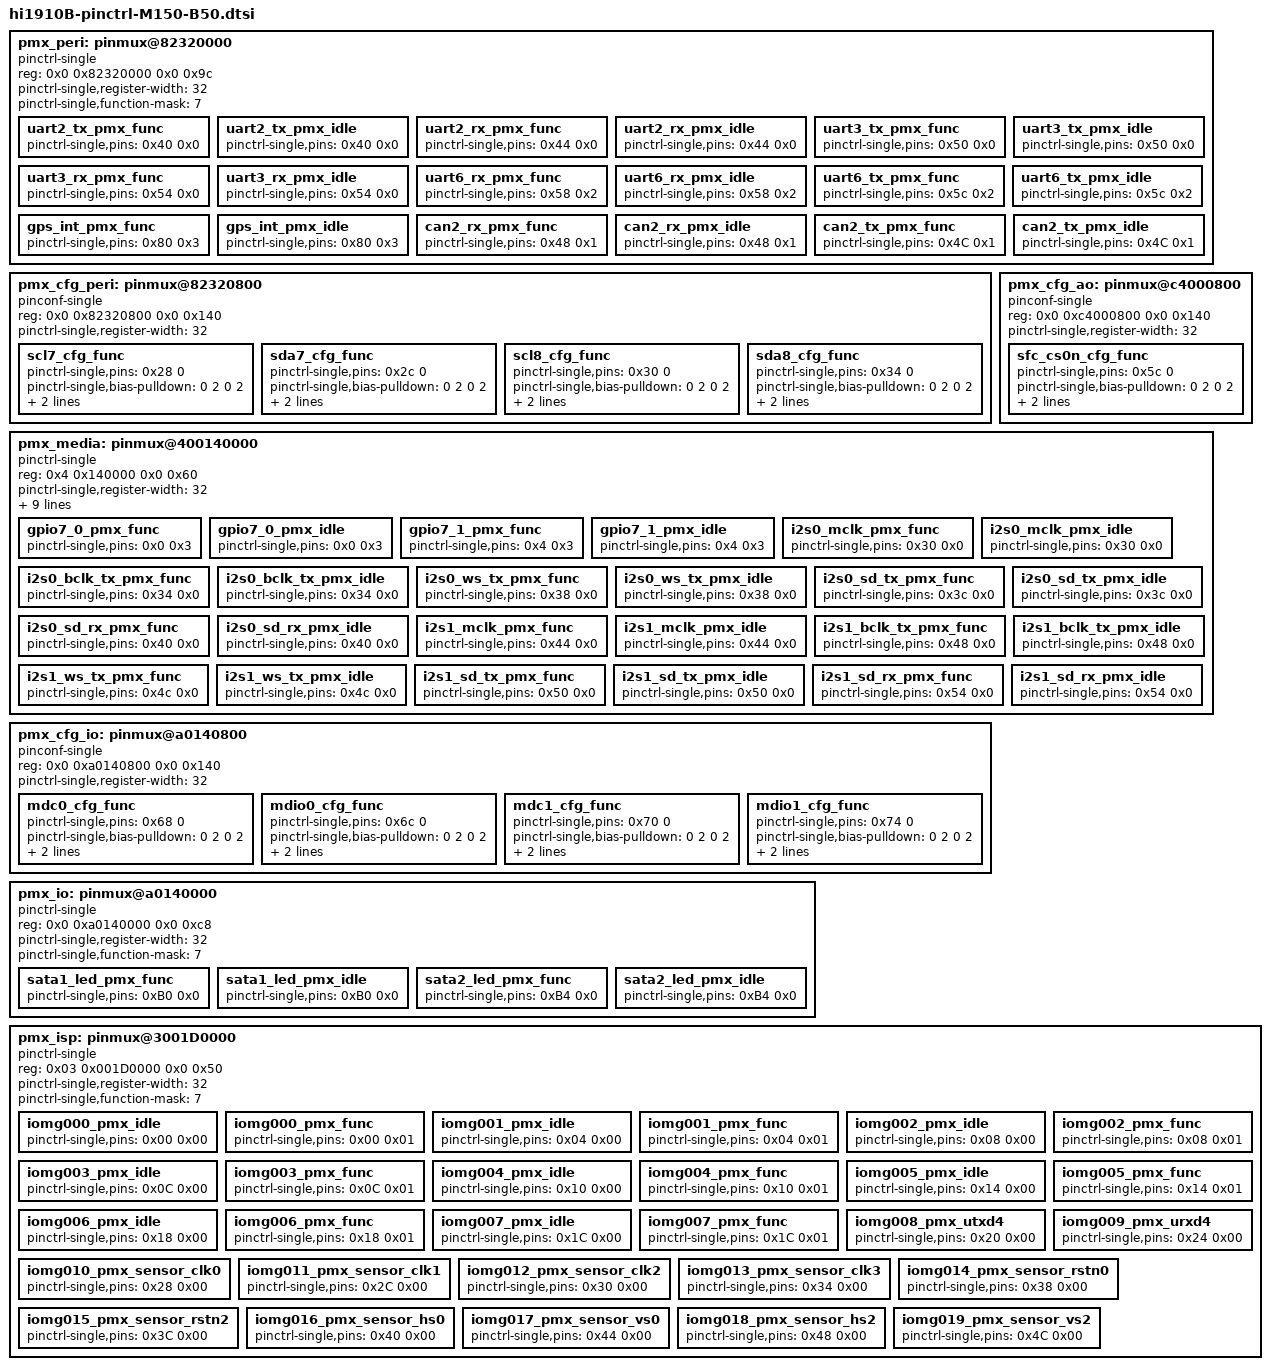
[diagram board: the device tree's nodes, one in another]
	pmx_peri: pinmux@82320000 {
		compatible = "pinctrl-single", "pinctrl-single1";
		reg = <0x0 0x82320000 0x0 0x9c>;
		#gpio-range-cells = <3>;
		pinctrl-single,register-width = <32>;
		pinctrl-single,function-mask = <7>;
		
		uart2_tx_pmx_func: uart2_tx_pmx_func {
			pinctrl-single,pins = <0x40    0x0>;
		};

		uart2_tx_pmx_idle: uart2_tx_pmx_idle {
			pinctrl-single,pins = <0x40    0x0>;
		};

		uart2_rx_pmx_func: uart2_rx_pmx_func {
			pinctrl-single,pins = <0x44    0x0>;
		};

		uart2_rx_pmx_idle: uart2_rx_pmx_idle {
			pinctrl-single,pins = <0x44    0x0>;
		};

		uart3_tx_pmx_func: uart3_tx_pmx_func {
			pinctrl-single,pins = <0x50    0x0>;
		};

		uart3_tx_pmx_idle: uart3_tx_pmx_idle {
			pinctrl-single,pins = <0x50    0x0>;
		};

		uart3_rx_pmx_func:uart3_rx_pmx_func {
			pinctrl-single,pins = <0x54    0x0>;
		};

		uart3_rx_pmx_idle: uart3_rx_pmx_idle {
			pinctrl-single,pins = <0x54    0x0>;
		};

                uart6_rx_pmx_func: uart6_rx_pmx_func {
                        pinctrl-single,pins = <0x58    0x2>;
                };

                uart6_rx_pmx_idle: uart6_rx_pmx_idle {
                        pinctrl-single,pins = <0x58    0x2>;
                };

                uart6_tx_pmx_func:uart6_tx_pmx_func {
                        pinctrl-single,pins = <0x5c    0x2>;
                };

                uart6_tx_pmx_idle: uart6_tx_pmx_idle {
                        pinctrl-single,pins = <0x5c    0x2>;
                };

                gps_int_pmx_func:gps_int_pmx_func {
                        pinctrl-single,pins = <0x80    0x3>;
                };

                gps_int_pmx_idle: gps_int_pmx_idle {
                        pinctrl-single,pins = <0x80    0x3>;
                };

		can2_rx_pmx_func: can2_rx_pmx_func {
			pinctrl-single,pins = <0x48    0x1>;
		};

		can2_rx_pmx_idle: can2_rx_pmx_idle {
			pinctrl-single,pins = <0x48    0x1>;
		};

		can2_tx_pmx_func: can2_tx_pmx_func {
			pinctrl-single,pins = <0x4C    0x1>;
		};

		can2_tx_pmx_idle: can2_tx_pmx_idle {
			pinctrl-single,pins = <0x4C    0x1>;
		};
	};

	pmx_cfg_peri: pinmux@82320800 {
		compatible = "pinconf-single", "pinctrl-single3";
		reg = <0x0 0x82320800 0x0 0x140>;
		pinctrl-single,register-width = <32>;
		#pinctrl-cells = <1>;

		scl7_cfg_func: scl7_cfg_func {
			pinctrl-single,pins = <0x28  0>;
			pinctrl-single,bias-pulldown = <0 2 0 2>;
			pinctrl-single,bias-pullup = <1 1 0 1>;
			pinctrl-single,drive-strength = <0xc0 0x1fff0>;
		};

                sda7_cfg_func: sda7_cfg_func {
                        pinctrl-single,pins = <0x2c  0>;
                        pinctrl-single,bias-pulldown = <0 2 0 2>;
                        pinctrl-single,bias-pullup = <1 1 0 1>;
                        pinctrl-single,drive-strength = <0xc0 0x1fff0>;
                };

                scl8_cfg_func: scl8_cfg_func {
                        pinctrl-single,pins = <0x30  0>;
                        pinctrl-single,bias-pulldown = <0 2 0 2>;
                        pinctrl-single,bias-pullup = <1 1 0 1>;
                        pinctrl-single,drive-strength = <0xc0 0x1fff0>;
                };

                sda8_cfg_func: sda8_cfg_func {
                        pinctrl-single,pins = <0x34  0>;
                        pinctrl-single,bias-pulldown = <0 2 0 2>;
                        pinctrl-single,bias-pullup = <1 1 0 1>;
                        pinctrl-single,drive-strength = <0xc0 0x1fff0>;
                };
	};

        pmx_cfg_ao: pinmux@c4000800 {
                compatible = "pinconf-single", "pinctrl-single3";
                reg = <0x0 0xc4000800 0x0 0x140>;
                pinctrl-single,register-width = <32>;
                #pinctrl-cells = <1>;

                sfc_cs0n_cfg_func: sfc_cs0n_cfg_func {
                        pinctrl-single,pins = <0x5c  0>;
                        pinctrl-single,bias-pulldown = <0 2 0 2>;
                        pinctrl-single,bias-pullup = <1 1 0 1>;
                        pinctrl-single,drive-strength = <0xb0 0x1fff0>;
                };
        };

	pmx_media: pinmux@400140000 {
		compatible = "pinctrl-single", "pinctrl-single1";
		reg = <0x4 0x140000 0x0 0x60>;
		#gpio-range-cells = <3>;
		pinctrl-single,register-width = <32>;
		pinctrl-single,function-mask = <7>;

		pinctrl-names = "default", "idle";
		pinctrl-0 = <&i2s0_mclk_pmx_func &i2s0_bclk_tx_pmx_func &i2s0_ws_tx_pmx_func &i2s0_sd_tx_pmx_func &i2s0_sd_rx_pmx_func &gpio7_0_pmx_func &gpio7_1_pmx_func>;
		pinctrl-1 = <&i2s1_mclk_pmx_idle &i2s1_bclk_tx_pmx_idle &i2s1_ws_tx_pmx_idle &i2s1_sd_tx_pmx_idle &i2s1_sd_rx_pmx_idle &gpio7_0_pmx_idle &gpio7_1_pmx_idle>;

               gpio7_0_pmx_func: gpio7_0_pmx_func {
                        pinctrl-single,pins = <0x0    0x3>;
                };

                gpio7_0_pmx_idle: gpio7_0_pmx_idle {
                        pinctrl-single,pins = <0x0    0x3>;
                };

                gpio7_1_pmx_func: gpio7_1_pmx_func {
                        pinctrl-single,pins = <0x4    0x3>;
                };

                gpio7_1_pmx_idle: gpio7_1_pmx_idle {
                        pinctrl-single,pins = <0x4    0x3>;
                };

		i2s0_mclk_pmx_func: i2s0_mclk_pmx_func {
			pinctrl-single,pins = <0x30    0x0>;
		};

		i2s0_mclk_pmx_idle: i2s0_mclk_pmx_idle {
			pinctrl-single,pins = <0x30    0x0>;
		};

		i2s0_bclk_tx_pmx_func: i2s0_bclk_tx_pmx_func {
			pinctrl-single,pins = <0x34    0x0>;
		};

		i2s0_bclk_tx_pmx_idle: i2s0_bclk_tx_pmx_idle {
			pinctrl-single,pins = <0x34    0x0>;
		};

		i2s0_ws_tx_pmx_func: i2s0_ws_tx_pmx_func {
			pinctrl-single,pins = <0x38    0x0>;
		};

		i2s0_ws_tx_pmx_idle: i2s0_ws_tx_pmx_idle {
			pinctrl-single,pins = <0x38    0x0>;
		};

		i2s0_sd_tx_pmx_func: i2s0_sd_tx_pmx_func {
			pinctrl-single,pins = <0x3c    0x0>;
		};

		i2s0_sd_tx_pmx_idle: i2s0_sd_tx_pmx_idle {
			pinctrl-single,pins = <0x3c    0x0>;
		};

		i2s0_sd_rx_pmx_func: i2s0_sd_rx_pmx_func {
			pinctrl-single,pins = <0x40    0x0>;
		};

		i2s0_sd_rx_pmx_idle: i2s0_sd_rx_pmx_idle {
			pinctrl-single,pins = <0x40    0x0>;
		};

		i2s1_mclk_pmx_func: i2s1_mclk_pmx_func {
			pinctrl-single,pins = <0x44    0x0>;
		};

		i2s1_mclk_pmx_idle: i2s1_mclk_pmx_idle {
			pinctrl-single,pins = <0x44    0x0>;
		};

		i2s1_bclk_tx_pmx_func: i2s1_bclk_tx_pmx_func {
			pinctrl-single,pins = <0x48    0x0>;
		};

		i2s1_bclk_tx_pmx_idle: i2s1_bclk_tx_pmx_idle {
			pinctrl-single,pins = <0x48    0x0>;
		};

		i2s1_ws_tx_pmx_func: i2s1_ws_tx_pmx_func {
			pinctrl-single,pins = <0x4c    0x0>;
		};

		i2s1_ws_tx_pmx_idle: i2s1_ws_tx_pmx_idle {
			pinctrl-single,pins = <0x4c    0x0>;
		};

		i2s1_sd_tx_pmx_func: i2s1_sd_tx_pmx_func {
			pinctrl-single,pins = <0x50    0x0>;
		};

		i2s1_sd_tx_pmx_idle: i2s1_sd_tx_pmx_idle {
			pinctrl-single,pins = <0x50    0x0>;
		};

		i2s1_sd_rx_pmx_func: i2s1_sd_rx_pmx_func {
			pinctrl-single,pins = <0x54    0x0>;
		};

		i2s1_sd_rx_pmx_idle: i2s1_sd_rx_pmx_idle {
			pinctrl-single,pins = <0x54    0x0>;
		};
	};

       pmx_cfg_io: pinmux@a0140800 {
                compatible = "pinconf-single", "pinctrl-single3";
                reg = <0x0 0xa0140800 0x0 0x140>;
                pinctrl-single,register-width = <32>;
                #pinctrl-cells = <1>;

                mdc0_cfg_func: mdc0_cfg_func {
                        pinctrl-single,pins = <0x68  0>;
                        pinctrl-single,bias-pulldown = <0 2 0 2>;
                        pinctrl-single,bias-pullup = <1 1 0 1>;
                        pinctrl-single,drive-strength = <0xa0 0x1fff0>;
                };

                mdio0_cfg_func: mdio0_cfg_func {
                        pinctrl-single,pins = <0x6c  0>;
                        pinctrl-single,bias-pulldown = <0 2 0 2>;
                        pinctrl-single,bias-pullup = <1 1 0 1>;
                        pinctrl-single,drive-strength = <0xa0 0x1fff0>;
                };

                mdc1_cfg_func: mdc1_cfg_func {
                        pinctrl-single,pins = <0x70  0>;
                        pinctrl-single,bias-pulldown = <0 2 0 2>;
                        pinctrl-single,bias-pullup = <1 1 0 1>;
                        pinctrl-single,drive-strength = <0xa0 0x1fff0>;
                };

                mdio1_cfg_func: mdio1_cfg_func {
                        pinctrl-single,pins = <0x74  0>;
                        pinctrl-single,bias-pulldown = <0 2 0 2>;
                        pinctrl-single,bias-pullup = <1 1 0 1>;
                        pinctrl-single,drive-strength = <0xa0 0x1fff0>;
                };
        };


        pmx_io: pinmux@a0140000 {
                compatible = "pinctrl-single", "pinctrl-single1";
                reg = <0x0 0xa0140000 0x0 0xc8>;
                #gpio-range-cells = <3>;
                pinctrl-single,register-width = <32>;
                pinctrl-single,function-mask = <7>;

                sata1_led_pmx_func: sata1_led_pmx_func {
                        pinctrl-single,pins = <0xB0    0x0>;
                };

                sata1_led_pmx_idle: sata1_led_pmx_idle {
                        pinctrl-single,pins = <0xB0    0x0>;
                };
                sata2_led_pmx_func: sata2_led_pmx_func {
                        pinctrl-single,pins = <0xB4    0x0>;
                };

                sata2_led_pmx_idle: sata2_led_pmx_idle {
                        pinctrl-single,pins = <0xB4    0x0>;
                };

	};

	pmx_isp: pinmux@3001D0000 {
		compatible = "pinctrl-single", "pinctrl-single1";
		reg = <0x03 0x001D0000 0x0 0x50>;
		#gpio-range-cells = <3>;
		pinctrl-single,register-width = <32>;
		pinctrl-single,function-mask = <7>;

		iomg000_pmx_idle: iomg000_pmx_idle {
			pinctrl-single,pins = <0x00    0x00>;
		};

		iomg000_pmx_func: iomg000_pmx_func {
			pinctrl-single,pins = <0x00    0x01>;
		};

		iomg001_pmx_idle: iomg001_pmx_idle {
			pinctrl-single,pins = <0x04    0x00>;
		};

		iomg001_pmx_func: iomg001_pmx_func {
			pinctrl-single,pins = <0x04    0x01>;
		};

		iomg002_pmx_idle: iomg002_pmx_idle {
			pinctrl-single,pins = <0x08    0x00>;
		};

		iomg002_pmx_func: iomg002_pmx_func {
			pinctrl-single,pins = <0x08    0x01>;
		};

		iomg003_pmx_idle: iomg003_pmx_idle {
			pinctrl-single,pins = <0x0C    0x00>;
		};

		iomg003_pmx_func: iomg003_pmx_func {
			pinctrl-single,pins = <0x0C    0x01>;
		};

		iomg004_pmx_idle: iomg004_pmx_idle {
			pinctrl-single,pins = <0x10    0x00>;
		};

		iomg004_pmx_func: iomg004_pmx_func {
			pinctrl-single,pins = <0x10    0x01>;
		};

		iomg005_pmx_idle: iomg005_pmx_idle {
			pinctrl-single,pins = <0x14    0x00>;
		};

		iomg005_pmx_func: iomg005_pmx_func {
			pinctrl-single,pins = <0x14    0x01>;
		};

		iomg006_pmx_idle: iomg006_pmx_idle {
			pinctrl-single,pins = <0x18    0x00>;
		};

		iomg006_pmx_func: iomg006_pmx_func {
			pinctrl-single,pins = <0x18    0x01>;
		};

		iomg007_pmx_idle: iomg007_pmx_idle {
			pinctrl-single,pins = <0x1C    0x00>;
		};

		iomg007_pmx_func: iomg007_pmx_func {
			pinctrl-single,pins = <0x1C    0x01>;
		};

		iomg008_pmx_utxd4: iomg008_pmx_utxd4 {
			pinctrl-single,pins = <0x20    0x00>;
		};

		iomg009_pmx_urxd4: iomg009_pmx_urxd4 {
			pinctrl-single,pins = <0x24    0x00>;
		};

		iomg010_pmx_sensor_clk0: iomg010_pmx_sensor_clk0 {
			pinctrl-single,pins = <0x28    0x00>;
		};

		iomg011_pmx_sensor_clk1: iomg011_pmx_sensor_clk1 {
			pinctrl-single,pins = <0x2C    0x00>;
		};

		iomg012_pmx_sensor_clk2: iomg012_pmx_sensor_clk2 {
			pinctrl-single,pins = <0x30    0x00>;
		};

		iomg013_pmx_sensor_clk3: iomg013_pmx_sensor_clk3 {
			pinctrl-single,pins = <0x34    0x00>;
		};

		iomg014_pmx_sensor_rstn0: iomg014_pmx_sensor_rstn0 {
			pinctrl-single,pins = <0x38    0x00>;
		};

		iomg015_pmx_sensor_rstn2: iomg015_pmx_sensor_rstn2 {
			pinctrl-single,pins = <0x3C    0x00>;
		};

		iomg016_pmx_sensor_hs0: iomg016_pmx_sensor_hs0 {
			pinctrl-single,pins = <0x40    0x00>;
		};

		iomg017_pmx_sensor_vs0: iomg017_pmx_sensor_vs0 {
			pinctrl-single,pins = <0x44    0x00>;
		};

		iomg018_pmx_sensor_hs2: iomg018_pmx_sensor_hs2 {
			pinctrl-single,pins = <0x48    0x00>;
		};

		iomg019_pmx_sensor_vs2: iomg019_pmx_sensor_vs2 {
			pinctrl-single,pins = <0x4C    0x00>;
		};
	};

